# HWRTOS_GMAC register map
Registers from a debugger description file.
Registers are 32-bit, access not given, no defined reset value unless marked. A register's access mark holds for its fields unless they carry their own. Addresses are absolute; registers are grouped by the start of their names; lines under a group give offsets from that group; [hi:lo] are bit positions; {n}, {i} and the like mark numbered series; 'fields as' and 'values as' point back to an identical list; <NAME> marks a mode.

## GMAC
0x400F000C GMAC_TXID ro
0x400F0010 GMAC_TXRESULT ro
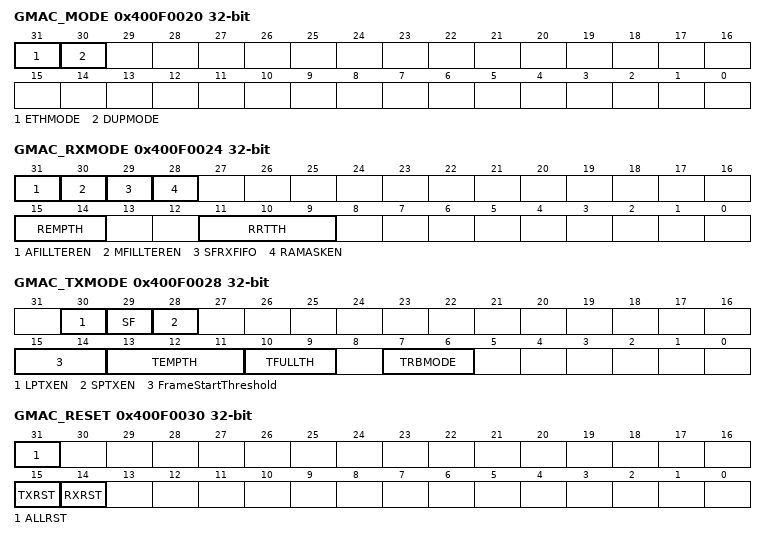
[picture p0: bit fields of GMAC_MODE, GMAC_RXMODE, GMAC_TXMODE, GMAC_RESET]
0x400F0020 GMAC_MODE
  [31] ETHMODE, [30] DUPMODE
0x400F0024 GMAC_RXMODE
  [31] AFILLTEREN, [30] MFILLTEREN, [29] SFRXFIFO, [28] RAMASKEN, [15:14] REMPTH, [11:9] RRTTH
0x400F0028 GMAC_TXMODE
  [30] LPTXEN, [29] SF, [28] SPTXEN, [15:14] FrameStartThreshold, [13:11] TEMPTH, [10:9] TFULLTH, [7:6] TRBMODE
0x400F0030 GMAC_RESET wo
  [31] ALLRST, [15] TXRST, [14] RXRST
{0x400F007C+4i} GMAC_PAUSE{i} (i=1..5)
  [31:0] PPDATA{i}
0x400F0098 GMAC_FLWCTL
  [31] PPRXEN
0x400F009C GMAC_PAUSPKT
  [31] PPR
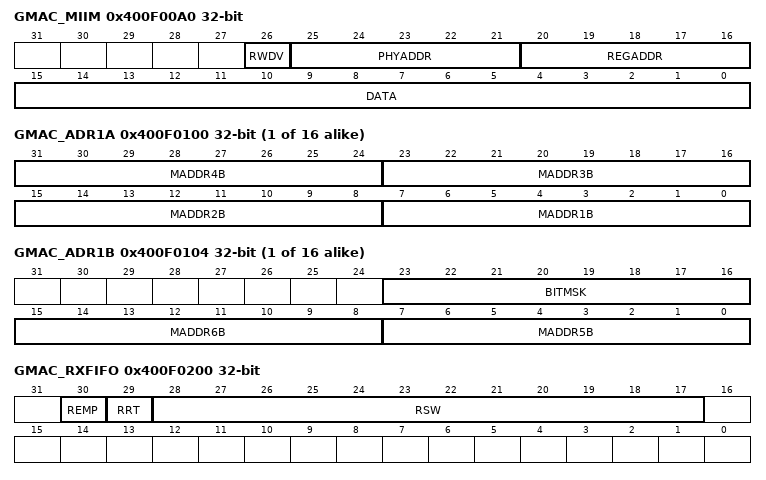
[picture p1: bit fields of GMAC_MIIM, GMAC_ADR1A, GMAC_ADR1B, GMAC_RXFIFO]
0x400F00A0 GMAC_MIIM
  [26] RWDV, [25:21] PHYADDR wo, [20:16] REGADDR wo, [15:0] DATA
{0x400F00F8+8i} GMAC_ADR{i}A (i=1..16)
  [8n-1:8n-8] MADDR{n}B (n=1..4)
{0x400F00FC+8i} GMAC_ADR{i}B (i=1..16)
  [23:16] BITMSK, [15:8] MADDR6B, [7:0] MADDR5B
0x400F0200 GMAC_RXFIFO ro
  [30] REMP, [29] RRT, [28:17] RSW
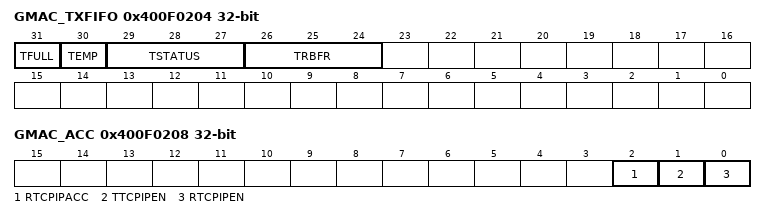
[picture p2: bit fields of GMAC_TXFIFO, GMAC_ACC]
0x400F0204 GMAC_TXFIFO ro
  [31] TFULL, [30] TEMP, [29:27] TSTATUS, [26:24] TRBFR
0x400F0208 GMAC_ACC
  [2] RTCPIPACC, [1] TTCPIPEN, [0] RTCPIPEN
0x400F0220 GMAC_RXMAC_ENA
  [0] RMACEN

## SFR
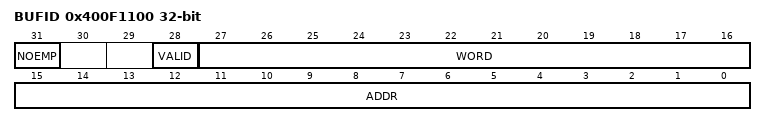
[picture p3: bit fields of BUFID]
0x400F1100 BUFID ro
  [31] NOEMP, [28] VALID, [27:16] WORD, [15:0] ADDR
